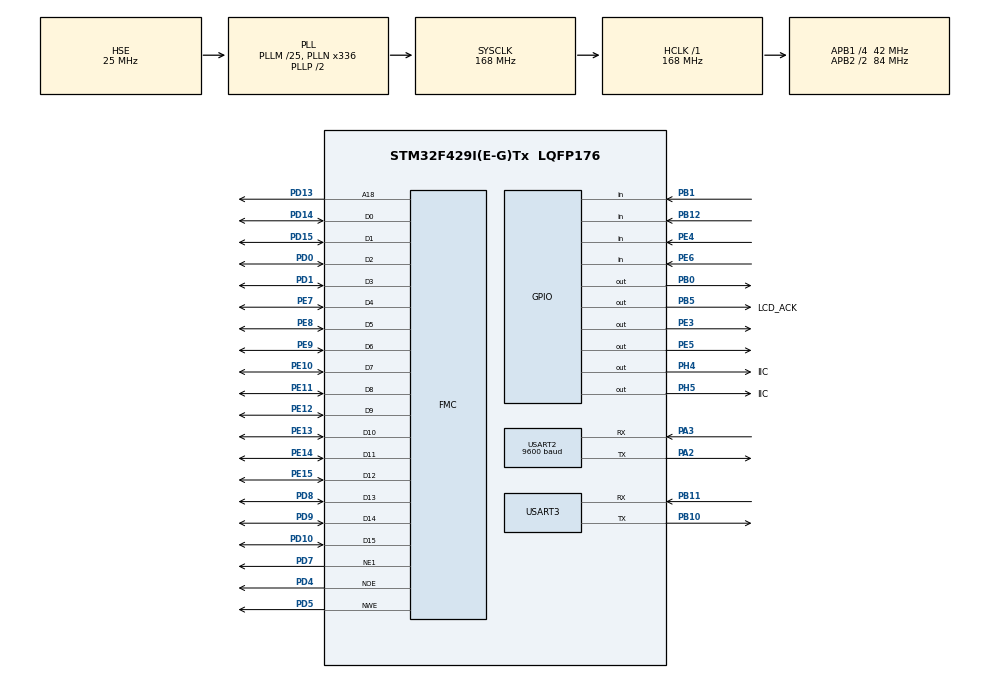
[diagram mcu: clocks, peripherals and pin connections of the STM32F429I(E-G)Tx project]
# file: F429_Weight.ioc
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FMC.BusTurnAroundDuration1=5
FMC.DataSetupTime1=60
Mcu.Family=STM32F4
Mcu.Name=STM32F429I(E-G)Tx
Mcu.Package=LQFP176
NVIC.PriorityGroup=NVIC_PRIORITYGROUP_4
NVIC.USART2_IRQn=true\:0\:0\:false\:false\:true\:true\:true
NVIC.USART3_IRQn=true\:0\:0\:false\:false\:true\:true\:true
PA2.Mode=Asynchronous
PA2.Signal=USART2_TX
PA3.Mode=Asynchronous
PA3.Signal=USART2_RX
PB0.GPIO_Speed=GPIO_SPEED_FREQ_HIGH
PB0.Signal=GPIO_Output
PB1.Signal=GPIO_Input
PB10.Mode=Asynchronous
PB10.Signal=USART3_TX
PB11.Mode=Asynchronous
PB11.Signal=USART3_RX
PB12.GPIO_PuPd=GPIO_PULLUP
PB12.Signal=GPIO_Input
PB5.GPIO_Label=LCD_ACK
PB5.GPIO_PuPd=GPIO_PULLUP
PB5.GPIO_Speed=GPIO_SPEED_FREQ_HIGH
PB5.Signal=GPIO_Output
PD0.Signal=FMC_D2_DA2
PD1.Signal=FMC_D3_DA3
PD10.Signal=FMC_D15_DA15
PD13.Signal=FMC_A18
PD14.Signal=FMC_D0_DA0
PD15.Signal=FMC_D1_DA1
PD4.Signal=FMC_NOE
PD5.Signal=FMC_NWE
PD7.Mode=NorPsramChipSelect1_1
PD7.Signal=FMC_NE1
PD8.Signal=FMC_D13_DA13
PD9.Signal=FMC_D14_DA14
PE10.Signal=FMC_D7_DA7
PE11.Signal=FMC_D8_DA8
PE12.Signal=FMC_D9_DA9
PE13.Signal=FMC_D10_DA10
PE14.Signal=FMC_D11_DA11
PE15.Signal=FMC_D12_DA12
PE3.GPIO_Speed=GPIO_SPEED_FREQ_HIGH
PE3.PinState=GPIO_PIN_SET
PE3.Signal=GPIO_Output
PE4.Signal=GPIO_Input
PE5.GPIO_PuPd=GPIO_NOPULL
PE5.GPIO_Speed=GPIO_SPEED_FREQ_HIGH
PE5.PinState=GPIO_PIN_SET
PE5.Signal=GPIO_Output
PE6.Signal=GPIO_Input
PE7.Signal=FMC_D4_DA4
PE8.Signal=FMC_D5_DA5
PE9.Signal=FMC_D6_DA6
PH0/OSC_IN.Mode=HSE-External-Oscillator
PH0/OSC_IN.Signal=RCC_OSC_IN
PH1/OSC_OUT.Mode=HSE-External-Oscillator
PH1/OSC_OUT.Signal=RCC_OSC_OUT
PH4.GPIO_Label=IIC
PH4.GPIO_ModeDefaultOutputPP=GPIO_MODE_OUTPUT_PP
PH4.GPIO_PuPd=GPIO_PULLUP
PH4.GPIO_Speed=GPIO_SPEED_FREQ_HIGH
PH4.PinState=GPIO_PIN_SET
PH4.Signal=GPIO_Output
PH5.GPIO_Label=IIC
PH5.GPIO_ModeDefaultOutputPP=GPIO_MODE_OUTPUT_PP
PH5.GPIO_PuPd=GPIO_PULLUP
PH5.GPIO_Speed=GPIO_SPEED_FREQ_HIGH
PH5.PinState=GPIO_PIN_SET
PH5.Signal=GPIO_Output
ProjectManager.HeapSize=0x200
ProjectManager.StackSize=0x400
ProjectManager.TargetToolchain=MDK-ARM V5
RCC.48MHZClocksFreq_Value=84000000
RCC.AHBFreq_Value=168000000
RCC.APB1CLKDivider=RCC_HCLK_DIV4
RCC.APB1Freq_Value=42000000
RCC.APB1TimFreq_Value=84000000
RCC.APB2CLKDivider=RCC_HCLK_DIV2
RCC.APB2Freq_Value=84000000
RCC.APB2TimFreq_Value=168000000
RCC.CortexFreq_Value=168000000
RCC.HCLKFreq_Value=168000000
RCC.HSE_VALUE=25000000
RCC.HSI_VALUE=16000000
RCC.LSE_VALUE=32768
RCC.PLLM=25
RCC.PLLN=336
RCC.PLLSourceVirtual=RCC_PLLSOURCE_HSE
RCC.SYSCLKFreq_VALUE=168000000
RCC.SYSCLKSource=RCC_SYSCLKSOURCE_PLLCLK
RCC.VCOOutputFreq_Value=336000000
SH.FMC_A18.0=FMC_A18,A18_1
SH.FMC_D0_DA0.0=FMC_D0,16b-d1
SH.FMC_D10_DA10.0=FMC_D10,16b-d1
SH.FMC_D11_DA11.0=FMC_D11,16b-d1
SH.FMC_D12_DA12.0=FMC_D12,16b-d1
SH.FMC_D13_DA13.0=FMC_D13,16b-d1
SH.FMC_D14_DA14.0=FMC_D14,16b-d1
SH.FMC_D15_DA15.0=FMC_D15,16b-d1
SH.FMC_D1_DA1.0=FMC_D1,16b-d1
SH.FMC_D2_DA2.0=FMC_D2,16b-d1
SH.FMC_D3_DA3.0=FMC_D3,16b-d1
SH.FMC_D4_DA4.0=FMC_D4,16b-d1
SH.FMC_D5_DA5.0=FMC_D5,16b-d1
SH.FMC_D6_DA6.0=FMC_D6,16b-d1
SH.FMC_D7_DA7.0=FMC_D7,16b-d1
SH.FMC_D8_DA8.0=FMC_D8,16b-d1
SH.FMC_D9_DA9.0=FMC_D9,16b-d1
SH.FMC_NOE.0=FMC_NOE,Lcd1
SH.FMC_NWE.0=FMC_NWE,Lcd1
USART2.BaudRate=9600
USART2.VirtualMode=VM_ASYNC
USART3.VirtualMode=VM_ASYNC
board=custom

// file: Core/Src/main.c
/* USER CODE BEGIN Header */
/**
  ******************************************************************************
  * @file           : main.c
  * @brief          : Main program body
  ******************************************************************************
  * @attention
  *
  * <h2><center>&copy; Copyright (c) 2021 STMicroelectronics.
  * All rights reserved.</center></h2>
  *
  * This software component is licensed by ST under BSD 3-Clause license,
  * the "License"; You may not use this file except in compliance with the
  * License. You may obtain a copy of the License at:
  *                        opensource.org/licenses/BSD-3-Clause
  *
  ******************************************************************************
  */
/* USER CODE END Header */
#include "main.h"
#include "usart.h"
#include "gpio.h"
#include "fmc.h"

/* USER CODE BEGIN Includes */
#include "user_init.h"
#include "tftlcd.h"
#include "stdio.h"
#include "hx711.h"
#include "sys.h"
/* USER CODE END Includes */

/* USER CODE BEGIN PV */
uint8_t buffer[100];  //LCD缓存

float weight_01;
/* USER CODE END PV */

void SystemClock_Config(void);

int main(void)
{

  /* MCU Configuration--------------------------------------------------------*/

  /* Reset of all peripherals, Initializes the Flash interface and the Systick. */
  HAL_Init();

  /* Configure the system clock */
  SystemClock_Config();

  /* Initialize all configured peripherals */
  MX_GPIO_Init();
  MX_FMC_Init();
  MX_USART2_UART_Init();
  MX_USART3_UART_Init();
  /* USER CODE BEGIN 2 */
	User_Init();
	TFTLCD_Fill(0,400,700,1000,GREEN);
  /* USER CODE END 2 */

  /* Infinite loop */
  while (1)
  {

    /* USER CODE BEGIN 3 */
		System_RunTask();
		//HAL_UART_Receive_IT(&huart3,(uint8_t *)data_buffer,1);
  }
  /* USER CODE END 3 */
}

void SystemClock_Config(void)
{
  RCC_OscInitTypeDef RCC_OscInitStruct = {0};
  RCC_ClkInitTypeDef RCC_ClkInitStruct = {0};

  /** Configure the main internal regulator output voltage
  */
  __HAL_RCC_PWR_CLK_ENABLE();
  __HAL_PWR_VOLTAGESCALING_CONFIG(PWR_REGULATOR_VOLTAGE_SCALE1);
  /** Initializes the RCC Oscillators according to the specified parameters
  * in the RCC_OscInitTypeDef structure.
  */
  RCC_OscInitStruct.OscillatorType = RCC_OSCILLATORTYPE_HSE;
  RCC_OscInitStruct.HSEState = RCC_HSE_ON;
  RCC_OscInitStruct.PLL.PLLState = RCC_PLL_ON;
  RCC_OscInitStruct.PLL.PLLSource = RCC_PLLSOURCE_HSE;
  RCC_OscInitStruct.PLL.PLLM = 25;
  RCC_OscInitStruct.PLL.PLLN = 336;
  RCC_OscInitStruct.PLL.PLLP = RCC_PLLP_DIV2;
  RCC_OscInitStruct.PLL.PLLQ = 4;
  if (HAL_RCC_OscConfig(&RCC_OscInitStruct) != HAL_OK)
  {
    Error_Handler();
  }
  /** Initializes the CPU, AHB and APB buses clocks
  */
  RCC_ClkInitStruct.ClockType = RCC_CLOCKTYPE_HCLK|RCC_CLOCKTYPE_SYSCLK
                              |RCC_CLOCKTYPE_PCLK1|RCC_CLOCKTYPE_PCLK2;
  RCC_ClkInitStruct.SYSCLKSource = RCC_SYSCLKSOURCE_PLLCLK;
  RCC_ClkInitStruct.AHBCLKDivider = RCC_SYSCLK_DIV1;
  RCC_ClkInitStruct.APB1CLKDivider = RCC_HCLK_DIV4;
  RCC_ClkInitStruct.APB2CLKDivider = RCC_HCLK_DIV2;

  if (HAL_RCC_ClockConfig(&RCC_ClkInitStruct, FLASH_LATENCY_5) != HAL_OK)
  {
    Error_Handler();
  }
}

void Error_Handler(void)
{
  __disable_irq();
  while (1)
  {
  }
}

/************************ (C) COPYRIGHT STMicroelectronics *****END OF FILE****/
